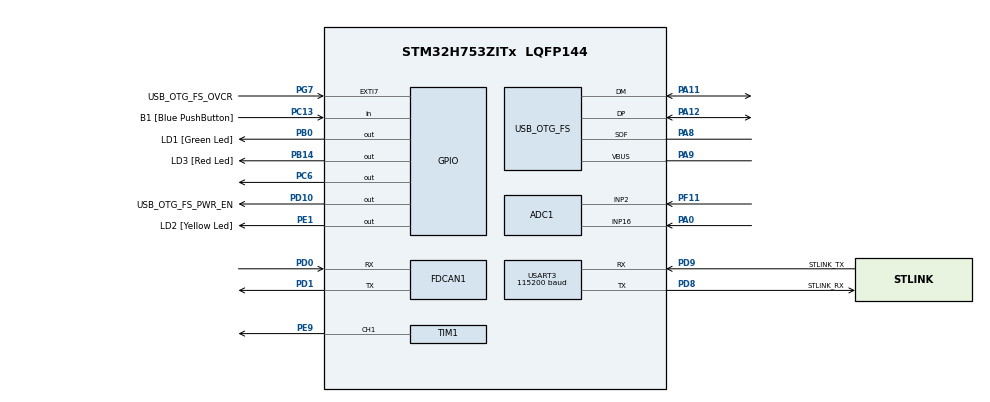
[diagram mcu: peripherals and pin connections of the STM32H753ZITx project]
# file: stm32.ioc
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ADC1.Channel-0\#ChannelRegularConversion=ADC_CHANNEL_16
ADC1.Channel-1\#ChannelRegularConversion=ADC_CHANNEL_2
ADC1.ConversionDataManagement=ADC_CONVERSIONDATA_DMA_CIRCULAR
ADC1.EOCSelection=ADC_EOC_SEQ_CONV
ADC1.NbrOfConversion=2
ADC1.NbrOfConversionFlag=1
ADC1.OffsetNumber-0\#ChannelRegularConversion=ADC_OFFSET_NONE
ADC1.OffsetNumber-1\#ChannelRegularConversion=ADC_OFFSET_NONE
ADC1.OffsetSignedSaturation-0\#ChannelRegularConversion=DISABLE
ADC1.OffsetSignedSaturation-1\#ChannelRegularConversion=DISABLE
ADC1.Overrun=ADC_OVR_DATA_OVERWRITTEN
ADC1.Rank-0\#ChannelRegularConversion=1
ADC1.Rank-1\#ChannelRegularConversion=2
ADC1.SamplingTime-0\#ChannelRegularConversion=ADC_SAMPLETIME_810CYCLES_5
ADC1.SamplingTime-1\#ChannelRegularConversion=ADC_SAMPLETIME_810CYCLES_5
ADC1.master=1
CORTEX_M7.AccessPermission-Cortex_Memory_Protection_Unit_Region0_Settings=MPU_REGION_FULL_ACCESS
CORTEX_M7.BaseAddress-Cortex_Memory_Protection_Unit_Region0_Settings=0x30000000
CORTEX_M7.CPU_DCache=Enabled
CORTEX_M7.CPU_ICache=Enabled
CORTEX_M7.DisableExec-Cortex_Memory_Protection_Unit_Region0_Settings=MPU_INSTRUCTION_ACCESS_DISABLE
CORTEX_M7.Enable-Cortex_Memory_Protection_Unit_Region0_Settings=MPU_REGION_ENABLE
CORTEX_M7.IsShareable-Cortex_Memory_Protection_Unit_Region0_Settings=MPU_ACCESS_SHAREABLE
CORTEX_M7.MPU_Control=MPU_PRIVILEGED_DEFAULT
CORTEX_M7.Size-Cortex_Memory_Protection_Unit_Region0_Settings=MPU_REGION_SIZE_256KB
Dma.ADC1.0.Direction=DMA_PERIPH_TO_MEMORY
Dma.ADC1.0.EventEnable=DISABLE
Dma.ADC1.0.FIFOMode=DMA_FIFOMODE_DISABLE
Dma.ADC1.0.Instance=DMA1_Stream0
Dma.ADC1.0.MemDataAlignment=DMA_MDATAALIGN_HALFWORD
Dma.ADC1.0.MemInc=DMA_MINC_ENABLE
Dma.ADC1.0.Mode=DMA_CIRCULAR
Dma.ADC1.0.PeriphDataAlignment=DMA_PDATAALIGN_HALFWORD
Dma.ADC1.0.PeriphInc=DMA_PINC_DISABLE
Dma.ADC1.0.Polarity=HAL_DMAMUX_REQ_GEN_RISING
Dma.ADC1.0.Priority=DMA_PRIORITY_LOW
Dma.ADC1.0.RequestNumber=1
Dma.ADC1.0.SignalID=NONE
Dma.ADC1.0.SyncEnable=DISABLE
Dma.ADC1.0.SyncPolarity=HAL_DMAMUX_SYNC_NO_EVENT
Dma.ADC1.0.SyncRequestNumber=1
Dma.ADC1.0.SyncSignalID=NONE
Dma.Request0=ADC1
FDCAN1.CalculateBaudRateNominal=500000
FDCAN1.CalculateTimeBitNominal=2000
FDCAN1.CalculateTimeQuantumNominal=250.0
FDCAN1.ClockCalibrationCCU=DISABLE
FDCAN1.Mode=FDCAN_MODE_INTERNAL_LOOPBACK
FDCAN1.NominalPrescaler=2
FDCAN1.NominalTimeSeg2=5
Mcu.Family=STM32H7
Mcu.Name=STM32H753ZITx
Mcu.Package=LQFP144
NVIC.ADC_IRQn=true\:0\:0\:true\:false\:true\:true\:true\:true
NVIC.DMA1_Stream0_IRQn=true\:0\:0\:true\:false\:true\:false\:true\:true
NVIC.PriorityGroup=NVIC_PRIORITYGROUP_4
PA0.Mode=IN16-Single-Ended
PA0.Signal=ADC1_INP16
PA1.Signal=ETH_REF_CLK
PA11.Mode=Device_Only
PA11.Signal=USB_OTG_FS_DM
PA12.Mode=Device_Only
PA12.Signal=USB_OTG_FS_DP
PA2.Signal=ETH_MDIO
PA7.Signal=ETH_CRS_DV
PA8.Mode=Activate_SOF_FS
PA8.Signal=USB_OTG_FS_SOF
PA9.Mode=Activate_VBUS
PA9.Signal=USB_OTG_FS_VBUS
PB0.GPIO_Label=LD1 [Green Led]
PB0.Signal=GPIO_Output
PB13.Signal=ETH_TXD1
PB14.GPIO_Label=LD3 [Red Led]
PB14.Signal=GPIO_Output
PC1.Signal=ETH_MDC
PC13.GPIO_Label=B1 [Blue PushButton]
PC13.Signal=GPIO_Input
PC14-OSC32_IN\ (OSC32_IN).Mode=LSE-External-Oscillator
PC14-OSC32_IN\ (OSC32_IN).Signal=RCC_OSC32_IN
PC15-OSC32_OUT\ (OSC32_OUT).Mode=LSE-External-Oscillator
PC15-OSC32_OUT\ (OSC32_OUT).Signal=RCC_OSC32_OUT
PC4.Signal=ETH_RXD0
PC5.Signal=ETH_RXD1
PC6.Signal=GPIO_Output
PD0.Mode=FDCAN_Activate
PD0.Signal=FDCAN1_RX
PD1.Mode=FDCAN_Activate
PD1.Signal=FDCAN1_TX
PD10.GPIO_Label=USB_OTG_FS_PWR_EN
PD10.Signal=GPIO_Output
PD8.GPIO_Label=STLINK_RX
PD8.Mode=Asynchronous
PD8.Signal=USART3_TX
PD9.GPIO_Label=STLINK_TX
PD9.Mode=Asynchronous
PD9.Signal=USART3_RX
PE1.GPIO_Label=LD2 [Yellow Led]
PE1.Signal=GPIO_Output
PE9.Signal=S_TIM1_CH1
PF11.Mode=IN2-Single-Ended
PF11.Signal=ADC1_INP2
PG11.Signal=ETH_TX_EN
PG13.Signal=ETH_TXD0
PG7.GPIO_Label=USB_OTG_FS_OVCR
PG7.Signal=GPXTI7
PH0-OSC_IN\ (PH0).Mode=HSE-External-Oscillator
PH0-OSC_IN\ (PH0).Signal=RCC_OSC_IN
PH1-OSC_OUT\ (PH1).Mode=HSE-External-Oscillator
PH1-OSC_OUT\ (PH1).Signal=RCC_OSC_OUT
ProjectManager.HeapSize=0x200
ProjectManager.StackSize=0x400
ProjectManager.TargetToolchain=Makefile
RCC.ADCFreq_Value=76000000
RCC.APB1Freq_Value=32000000
RCC.APB2Freq_Value=64000000
RCC.APB3Freq_Value=64000000
RCC.APB4Freq_Value=64000000
RCC.CortexFreq_Value=64000000
RCC.D2PPRE1=RCC_APB1_DIV2
RCC.DIVM1=1
RCC.DIVM2=1
RCC.DIVN1=19
RCC.DIVN2=19
RCC.DIVQ1=3
RCC.FDCANCLockSelection=RCC_FDCANCLKSOURCE_HSE
RCC.HCLKFreq_Value=64000000
RCC.HSE_VALUE=8000000
RCC.PLL2FRACN=0
RCC.PLL3FRACN=0
RCC.PLLFRACN=0
RCC.SYSCLKFreq_VALUE=64000000
RCC.USBFreq_Value=50666666.666666664
SH.S_TIM1_CH1.0=TIM1_CH1,PWM Generation1 CH1
TIM1.Channel-PWM\ Generation1\ CH1=TIM_CHANNEL_1
TIM1.Prescaler=0
USART3.AutoBaudRateEnableParam=UART_ADVFEATURE_AUTOBAUDRATE_DISABLE
USART3.BaudRate=115200
USART3.ClockPrescaler=PRESCALER_DIV1
USART3.DMADisableonRxErrorParam=ADVFEATURE_DMA_ENABLEONRXERROR
USART3.DataInvertParam=ADVFEATURE_DATAINV_DISABLE
USART3.FIFOMode=FIFOMODE_DISABLE
USART3.MSBFirstParam=ADVFEATURE_MSBFIRST_DISABLE
USART3.Mode=MODE_TX_RX
USART3.OneBitSampling=UART_ONE_BIT_SAMPLE_DISABLE
USART3.OverSampling=UART_OVERSAMPLING_16
USART3.OverrunDisableParam=ADVFEATURE_OVERRUN_ENABLE
USART3.Parity=PARITY_NONE
USART3.RXFIFOThreshold=RXFIFO_THRESHOLD_1EIGHTHFULL
USART3.RxPinLevelInvertParam=ADVFEATURE_RXINV_DISABLE
USART3.StopBits=STOPBITS_1
USART3.SwapParam=ADVFEATURE_SWAP_DISABLE
USART3.TXFIFOThreshold=TXFIFO_THRESHOLD_1EIGHTHFULL
USART3.TxPinLevelInvertParam=ADVFEATURE_TXINV_DISABLE
USART3.VirtualMode-Asynchronous=VM_ASYNC
USART3.WordLength=WORDLENGTH_8B
USB_OTG_FS.Sof_enable=ENABLE
USB_OTG_FS.VirtualMode=Device_Only
USB_OTG_FS.battery_charging_enable=ENABLE
USB_OTG_FS.low_power_enable=DISABLE
USB_OTG_FS.lpm_enable=DISABLE
USB_OTG_FS.use_dedicated_ep1=DISABLE
USB_OTG_FS.vbus_sensing_enable=ENABLE
VP_MEMORYMAP_VS_MEMORYMAP.Mode=CurAppReg
board=NUCLEO-H753ZI

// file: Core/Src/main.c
/* USER CODE BEGIN Header */
/**
  ******************************************************************************
  * @file           : main.c
  * @brief          : Main program body
  ******************************************************************************
  * @attention
  *
  * Copyright (c) 2025 STMicroelectronics.
  * All rights reserved.
  *
  * This software is licensed under terms that can be found in the LICENSE file
  * in the root directory of this software component.
  * If no LICENSE file comes with this software, it is provided AS-IS.
  *
  ******************************************************************************
  */
/* USER CODE END Header */
#include "main.h"

/* USER CODE BEGIN Includes */

#include <entry.h>

/* USER CODE END Includes */

ADC_HandleTypeDef hadc1;
DMA_HandleTypeDef hdma_adc1;

FDCAN_HandleTypeDef hfdcan1;

TIM_HandleTypeDef htim1;

UART_HandleTypeDef huart3;

PCD_HandleTypeDef hpcd_USB_OTG_FS;

void SystemClock_Config(void);
static void MPU_Config(void);
static void MX_GPIO_Init(void);
static void MX_DMA_Init(void);
static void MX_USART3_UART_Init(void);
static void MX_USB_OTG_FS_PCD_Init(void);
static void MX_ADC1_Init(void);
static void MX_TIM1_Init(void);
static void MX_FDCAN1_Init(void);

int main(void)
{

  /* MPU Configuration--------------------------------------------------------*/
  MPU_Config();

  /* Enable the CPU Cache */

  /* Enable I-Cache---------------------------------------------------------*/
  SCB_EnableICache();

  /* Enable D-Cache---------------------------------------------------------*/
  SCB_EnableDCache();

  /* MCU Configuration--------------------------------------------------------*/

  /* Reset of all peripherals, Initializes the Flash interface and the Systick. */
  HAL_Init();

  /* Configure the system clock */
  SystemClock_Config();

  /* Initialize all configured peripherals */
  MX_GPIO_Init();
  MX_DMA_Init();
  MX_USART3_UART_Init();
  MX_USB_OTG_FS_PCD_Init();
  MX_ADC1_Init();
  MX_TIM1_Init();
  MX_FDCAN1_Init();
  /* USER CODE BEGIN 2 */

  __initHandler();

  /* USER CODE END 2 */

  /* Infinite loop */
  while (1)
  {

  }
}

void SystemClock_Config(void)
{
  RCC_OscInitTypeDef RCC_OscInitStruct = {0};
  RCC_ClkInitTypeDef RCC_ClkInitStruct = {0};

  /** Supply configuration update enable
  */
  HAL_PWREx_ConfigSupply(PWR_LDO_SUPPLY);

  /** Configure the main internal regulator output voltage
  */
  __HAL_PWR_VOLTAGESCALING_CONFIG(PWR_REGULATOR_VOLTAGE_SCALE3);

  while(!__HAL_PWR_GET_FLAG(PWR_FLAG_VOSRDY)) {}

  /** Initializes the RCC Oscillators according to the specified parameters
  * in the RCC_OscInitTypeDef structure.
  */
  RCC_OscInitStruct.OscillatorType = RCC_OSCILLATORTYPE_HSI|RCC_OSCILLATORTYPE_HSE;
  RCC_OscInitStruct.HSEState = RCC_HSE_ON;
  RCC_OscInitStruct.HSIState = RCC_HSI_DIV1;
  RCC_OscInitStruct.HSICalibrationValue = RCC_HSICALIBRATION_DEFAULT;
  RCC_OscInitStruct.PLL.PLLState = RCC_PLL_ON;
  RCC_OscInitStruct.PLL.PLLSource = RCC_PLLSOURCE_HSE;
  RCC_OscInitStruct.PLL.PLLM = 1;
  RCC_OscInitStruct.PLL.PLLN = 19;
  RCC_OscInitStruct.PLL.PLLP = 2;
  RCC_OscInitStruct.PLL.PLLQ = 3;
  RCC_OscInitStruct.PLL.PLLR = 2;
  RCC_OscInitStruct.PLL.PLLRGE = RCC_PLL1VCIRANGE_3;
  RCC_OscInitStruct.PLL.PLLVCOSEL = RCC_PLL1VCOMEDIUM;
  RCC_OscInitStruct.PLL.PLLFRACN = 0;
  if (HAL_RCC_OscConfig(&RCC_OscInitStruct) != HAL_OK)
  {
    Error_Handler();
  }

  /** Initializes the CPU, AHB and APB buses clocks
  */
  RCC_ClkInitStruct.ClockType = RCC_CLOCKTYPE_HCLK|RCC_CLOCKTYPE_SYSCLK
                              |RCC_CLOCKTYPE_PCLK1|RCC_CLOCKTYPE_PCLK2
                              |RCC_CLOCKTYPE_D3PCLK1|RCC_CLOCKTYPE_D1PCLK1;
  RCC_ClkInitStruct.SYSCLKSource = RCC_SYSCLKSOURCE_HSI;
  RCC_ClkInitStruct.SYSCLKDivider = RCC_SYSCLK_DIV1;
  RCC_ClkInitStruct.AHBCLKDivider = RCC_HCLK_DIV1;
  RCC_ClkInitStruct.APB3CLKDivider = RCC_APB3_DIV1;
  RCC_ClkInitStruct.APB1CLKDivider = RCC_APB1_DIV2;
  RCC_ClkInitStruct.APB2CLKDivider = RCC_APB2_DIV1;
  RCC_ClkInitStruct.APB4CLKDivider = RCC_APB4_DIV1;

  if (HAL_RCC_ClockConfig(&RCC_ClkInitStruct, FLASH_LATENCY_1) != HAL_OK)
  {
    Error_Handler();
  }
}

static void MX_ADC1_Init(void)
{

  ADC_MultiModeTypeDef multimode = {0};
  ADC_ChannelConfTypeDef sConfig = {0};

  /** Common config
  */
  hadc1.Instance = ADC1;
  hadc1.Init.ScanConvMode = ADC_SCAN_ENABLE;
  hadc1.Init.EOCSelection = ADC_EOC_SEQ_CONV;
  hadc1.Init.LowPowerAutoWait = DISABLE;
  hadc1.Init.ContinuousConvMode = DISABLE;
  hadc1.Init.NbrOfConversion = 2;
  hadc1.Init.DiscontinuousConvMode = DISABLE;
  hadc1.Init.ExternalTrigConv = ADC_SOFTWARE_START;
  hadc1.Init.ExternalTrigConvEdge = ADC_EXTERNALTRIGCONVEDGE_NONE;
  hadc1.Init.ConversionDataManagement = ADC_CONVERSIONDATA_DMA_CIRCULAR;
  hadc1.Init.Overrun = ADC_OVR_DATA_OVERWRITTEN;
  hadc1.Init.LeftBitShift = ADC_LEFTBITSHIFT_NONE;
  hadc1.Init.OversamplingMode = DISABLE;
  hadc1.Init.Oversampling.Ratio = 1;
  if (HAL_ADC_Init(&hadc1) != HAL_OK)
  {
    Error_Handler();
  }
  hadc1.Init.ClockPrescaler = ADC_CLOCK_ASYNC_DIV2;
  hadc1.Init.Resolution = ADC_RESOLUTION_16B;
  if (HAL_ADC_Init(&hadc1) != HAL_OK)
  {
    Error_Handler();
  }

  /** Configure the ADC multi-mode
  */
  multimode.Mode = ADC_MODE_INDEPENDENT;
  if (HAL_ADCEx_MultiModeConfigChannel(&hadc1, &multimode) != HAL_OK)
  {
    Error_Handler();
  }

  /** Configure Regular Channel
  */
  sConfig.Channel = ADC_CHANNEL_16;
  sConfig.Rank = ADC_REGULAR_RANK_1;
  sConfig.SamplingTime = ADC_SAMPLETIME_810CYCLES_5;
  sConfig.SingleDiff = ADC_SINGLE_ENDED;
  sConfig.OffsetNumber = ADC_OFFSET_NONE;
  sConfig.Offset = 0;
  sConfig.OffsetSignedSaturation = DISABLE;
  if (HAL_ADC_ConfigChannel(&hadc1, &sConfig) != HAL_OK)
  {
    Error_Handler();
  }

  /** Configure Regular Channel
  */
  sConfig.Channel = ADC_CHANNEL_2;
  sConfig.Rank = ADC_REGULAR_RANK_2;
  if (HAL_ADC_ConfigChannel(&hadc1, &sConfig) != HAL_OK)
  {
    Error_Handler();
  }

}

static void MX_FDCAN1_Init(void)
{

  hfdcan1.Instance = FDCAN1;
  hfdcan1.Init.FrameFormat = FDCAN_FRAME_CLASSIC;
  hfdcan1.Init.Mode = FDCAN_MODE_INTERNAL_LOOPBACK;
  hfdcan1.Init.AutoRetransmission = DISABLE;
  hfdcan1.Init.TransmitPause = DISABLE;
  hfdcan1.Init.ProtocolException = DISABLE;
  hfdcan1.Init.NominalPrescaler = 2;
  hfdcan1.Init.NominalSyncJumpWidth = 1;
  hfdcan1.Init.NominalTimeSeg1 = 2;
  hfdcan1.Init.NominalTimeSeg2 = 5;
  hfdcan1.Init.DataPrescaler = 1;
  hfdcan1.Init.DataSyncJumpWidth = 1;
  hfdcan1.Init.DataTimeSeg1 = 1;
  hfdcan1.Init.DataTimeSeg2 = 1;
  hfdcan1.Init.MessageRAMOffset = 0;
  hfdcan1.Init.StdFiltersNbr = 0;
  hfdcan1.Init.ExtFiltersNbr = 0;
  hfdcan1.Init.RxFifo0ElmtsNbr = 0;
  hfdcan1.Init.RxFifo0ElmtSize = FDCAN_DATA_BYTES_8;
  hfdcan1.Init.RxFifo1ElmtsNbr = 0;
  hfdcan1.Init.RxFifo1ElmtSize = FDCAN_DATA_BYTES_8;
  hfdcan1.Init.RxBuffersNbr = 0;
  hfdcan1.Init.RxBufferSize = FDCAN_DATA_BYTES_8;
  hfdcan1.Init.TxEventsNbr = 0;
  hfdcan1.Init.TxBuffersNbr = 0;
  hfdcan1.Init.TxFifoQueueElmtsNbr = 0;
  hfdcan1.Init.TxFifoQueueMode = FDCAN_TX_FIFO_OPERATION;
  hfdcan1.Init.TxElmtSize = FDCAN_DATA_BYTES_8;
  if (HAL_FDCAN_Init(&hfdcan1) != HAL_OK)
  {
    Error_Handler();
  }

}

static void MX_TIM1_Init(void)
{

  TIM_MasterConfigTypeDef sMasterConfig = {0};
  TIM_OC_InitTypeDef sConfigOC = {0};
  TIM_BreakDeadTimeConfigTypeDef sBreakDeadTimeConfig = {0};

  htim1.Instance = TIM1;
  htim1.Init.Prescaler = 0;
  htim1.Init.CounterMode = TIM_COUNTERMODE_UP;
  htim1.Init.Period = 65535;
  htim1.Init.ClockDivision = TIM_CLOCKDIVISION_DIV1;
  htim1.Init.RepetitionCounter = 0;
  htim1.Init.AutoReloadPreload = TIM_AUTORELOAD_PRELOAD_DISABLE;
  if (HAL_TIM_PWM_Init(&htim1) != HAL_OK)
  {
    Error_Handler();
  }
  sMasterConfig.MasterOutputTrigger = TIM_TRGO_RESET;
  sMasterConfig.MasterOutputTrigger2 = TIM_TRGO2_RESET;
  sMasterConfig.MasterSlaveMode = TIM_MASTERSLAVEMODE_DISABLE;
  if (HAL_TIMEx_MasterConfigSynchronization(&htim1, &sMasterConfig) != HAL_OK)
  {
    Error_Handler();
  }
  sConfigOC.OCMode = TIM_OCMODE_PWM1;
  sConfigOC.Pulse = 0;
  sConfigOC.OCPolarity = TIM_OCPOLARITY_HIGH;
  sConfigOC.OCNPolarity = TIM_OCNPOLARITY_HIGH;
  sConfigOC.OCFastMode = TIM_OCFAST_DISABLE;
  sConfigOC.OCIdleState = TIM_OCIDLESTATE_RESET;
  sConfigOC.OCNIdleState = TIM_OCNIDLESTATE_RESET;
  if (HAL_TIM_PWM_ConfigChannel(&htim1, &sConfigOC, TIM_CHANNEL_1) != HAL_OK)
  {
    Error_Handler();
  }
  sBreakDeadTimeConfig.OffStateRunMode = TIM_OSSR_DISABLE;
  sBreakDeadTimeConfig.OffStateIDLEMode = TIM_OSSI_DISABLE;
  sBreakDeadTimeConfig.LockLevel = TIM_LOCKLEVEL_OFF;
  sBreakDeadTimeConfig.DeadTime = 0;
  sBreakDeadTimeConfig.BreakState = TIM_BREAK_DISABLE;
  sBreakDeadTimeConfig.BreakPolarity = TIM_BREAKPOLARITY_HIGH;
  sBreakDeadTimeConfig.BreakFilter = 0;
  sBreakDeadTimeConfig.Break2State = TIM_BREAK2_DISABLE;
  sBreakDeadTimeConfig.Break2Polarity = TIM_BREAK2POLARITY_HIGH;
  sBreakDeadTimeConfig.Break2Filter = 0;
  sBreakDeadTimeConfig.AutomaticOutput = TIM_AUTOMATICOUTPUT_DISABLE;
  if (HAL_TIMEx_ConfigBreakDeadTime(&htim1, &sBreakDeadTimeConfig) != HAL_OK)
  {
    Error_Handler();
  }
  HAL_TIM_MspPostInit(&htim1);

}

static void MX_USART3_UART_Init(void)
{

  huart3.Instance = USART3;
  huart3.Init.BaudRate = 115200;
  huart3.Init.WordLength = UART_WORDLENGTH_8B;
  huart3.Init.StopBits = UART_STOPBITS_1;
  huart3.Init.Parity = UART_PARITY_NONE;
  huart3.Init.Mode = UART_MODE_TX_RX;
  huart3.Init.HwFlowCtl = UART_HWCONTROL_NONE;
  huart3.Init.OverSampling = UART_OVERSAMPLING_16;
  huart3.Init.OneBitSampling = UART_ONE_BIT_SAMPLE_DISABLE;
  huart3.Init.ClockPrescaler = UART_PRESCALER_DIV1;
  huart3.AdvancedInit.AdvFeatureInit = UART_ADVFEATURE_NO_INIT;
  if (HAL_UART_Init(&huart3) != HAL_OK)
  {
    Error_Handler();
  }
  if (HAL_UARTEx_SetTxFifoThreshold(&huart3, UART_TXFIFO_THRESHOLD_1_8) != HAL_OK)
  {
    Error_Handler();
  }
  if (HAL_UARTEx_SetRxFifoThreshold(&huart3, UART_RXFIFO_THRESHOLD_1_8) != HAL_OK)
  {
    Error_Handler();
  }
  if (HAL_UARTEx_DisableFifoMode(&huart3) != HAL_OK)
  {
    Error_Handler();
  }

}

static void MX_USB_OTG_FS_PCD_Init(void)
{

  hpcd_USB_OTG_FS.Instance = USB_OTG_FS;
  hpcd_USB_OTG_FS.Init.dev_endpoints = 9;
  hpcd_USB_OTG_FS.Init.speed = PCD_SPEED_FULL;
  hpcd_USB_OTG_FS.Init.dma_enable = DISABLE;
  hpcd_USB_OTG_FS.Init.phy_itface = PCD_PHY_EMBEDDED;
  hpcd_USB_OTG_FS.Init.Sof_enable = ENABLE;
  hpcd_USB_OTG_FS.Init.low_power_enable = DISABLE;
  hpcd_USB_OTG_FS.Init.lpm_enable = DISABLE;
  hpcd_USB_OTG_FS.Init.battery_charging_enable = ENABLE;
  hpcd_USB_OTG_FS.Init.vbus_sensing_enable = ENABLE;
  hpcd_USB_OTG_FS.Init.use_dedicated_ep1 = DISABLE;
  if (HAL_PCD_Init(&hpcd_USB_OTG_FS) != HAL_OK)
  {
    Error_Handler();
  }

}

static void MX_DMA_Init(void)
{

  /* DMA controller clock enable */
  __HAL_RCC_DMA1_CLK_ENABLE();

  /* DMA interrupt init */
  /* DMA1_Stream0_IRQn interrupt configuration */
  HAL_NVIC_SetPriority(DMA1_Stream0_IRQn, 0, 0);
  HAL_NVIC_EnableIRQ(DMA1_Stream0_IRQn);

}

static void MX_GPIO_Init(void)
{
  GPIO_InitTypeDef GPIO_InitStruct = {0};

  /* GPIO Ports Clock Enable */
  __HAL_RCC_GPIOC_CLK_ENABLE();
  __HAL_RCC_GPIOH_CLK_ENABLE();
  __HAL_RCC_GPIOA_CLK_ENABLE();
  __HAL_RCC_GPIOB_CLK_ENABLE();
  __HAL_RCC_GPIOF_CLK_ENABLE();
  __HAL_RCC_GPIOE_CLK_ENABLE();
  __HAL_RCC_GPIOD_CLK_ENABLE();
  __HAL_RCC_GPIOG_CLK_ENABLE();

  /*Configure GPIO pin Output Level */
  HAL_GPIO_WritePin(GPIOB, LD1_Pin|LD3_Pin, GPIO_PIN_RESET);

  /*Configure GPIO pin Output Level */
  HAL_GPIO_WritePin(USB_OTG_FS_PWR_EN_GPIO_Port, USB_OTG_FS_PWR_EN_Pin, GPIO_PIN_RESET);

  /*Configure GPIO pin Output Level */
  HAL_GPIO_WritePin(GPIOC, GPIO_PIN_6, GPIO_PIN_RESET);

  /*Configure GPIO pin Output Level */
  HAL_GPIO_WritePin(LD2_GPIO_Port, LD2_Pin, GPIO_PIN_RESET);

  /*Configure GPIO pin : B1_Pin */
  GPIO_InitStruct.Pin = B1_Pin;
  GPIO_InitStruct.Mode = GPIO_MODE_INPUT;
  GPIO_InitStruct.Pull = GPIO_NOPULL;
  HAL_GPIO_Init(B1_GPIO_Port, &GPIO_InitStruct);

  /*Configure GPIO pins : PC1 PC4 PC5 */
  GPIO_InitStruct.Pin = GPIO_PIN_1|GPIO_PIN_4|GPIO_PIN_5;
  GPIO_InitStruct.Mode = GPIO_MODE_AF_PP;
  GPIO_InitStruct.Pull = GPIO_NOPULL;
  GPIO_InitStruct.Speed = GPIO_SPEED_FREQ_LOW;
  GPIO_InitStruct.Alternate = GPIO_AF11_ETH;
  HAL_GPIO_Init(GPIOC, &GPIO_InitStruct);

  /*Configure GPIO pins : PA1 PA2 PA7 */
  GPIO_InitStruct.Pin = GPIO_PIN_1|GPIO_PIN_2|GPIO_PIN_7;
  GPIO_InitStruct.Mode = GPIO_MODE_AF_PP;
  GPIO_InitStruct.Pull = GPIO_NOPULL;
  GPIO_InitStruct.Speed = GPIO_SPEED_FREQ_LOW;
  GPIO_InitStruct.Alternate = GPIO_AF11_ETH;
  HAL_GPIO_Init(GPIOA, &GPIO_InitStruct);

  /*Configure GPIO pins : LD1_Pin LD3_Pin */
  GPIO_InitStruct.Pin = LD1_Pin|LD3_Pin;
  GPIO_InitStruct.Mode = GPIO_MODE_OUTPUT_PP;
  GPIO_InitStruct.Pull = GPIO_NOPULL;
  GPIO_InitStruct.Speed = GPIO_SPEED_FREQ_LOW;
  HAL_GPIO_Init(GPIOB, &GPIO_InitStruct);

  /*Configure GPIO pin : PB13 */
  GPIO_InitStruct.Pin = GPIO_PIN_13;
  GPIO_InitStruct.Mode = GPIO_MODE_AF_PP;
  GPIO_InitStruct.Pull = GPIO_NOPULL;
  GPIO_InitStruct.Speed = GPIO_SPEED_FREQ_LOW;
  GPIO_InitStruct.Alternate = GPIO_AF11_ETH;
  HAL_GPIO_Init(GPIOB, &GPIO_InitStruct);

  /*Configure GPIO pin : USB_OTG_FS_PWR_EN_Pin */
  GPIO_InitStruct.Pin = USB_OTG_FS_PWR_EN_Pin;
  GPIO_InitStruct.Mode = GPIO_MODE_OUTPUT_PP;
  GPIO_InitStruct.Pull = GPIO_NOPULL;
  GPIO_InitStruct.Speed = GPIO_SPEED_FREQ_LOW;
  HAL_GPIO_Init(USB_OTG_FS_PWR_EN_GPIO_Port, &GPIO_InitStruct);

  /*Configure GPIO pin : USB_OTG_FS_OVCR_Pin */
  GPIO_InitStruct.Pin = USB_OTG_FS_OVCR_Pin;
  GPIO_InitStruct.Mode = GPIO_MODE_IT_RISING;
  GPIO_InitStruct.Pull = GPIO_NOPULL;
  HAL_GPIO_Init(USB_OTG_FS_OVCR_GPIO_Port, &GPIO_InitStruct);

  /*Configure GPIO pin : PC6 */
  GPIO_InitStruct.Pin = GPIO_PIN_6;
  GPIO_InitStruct.Mode = GPIO_MODE_OUTPUT_PP;
  GPIO_InitStruct.Pull = GPIO_NOPULL;
  GPIO_InitStruct.Speed = GPIO_SPEED_FREQ_LOW;
  HAL_GPIO_Init(GPIOC, &GPIO_InitStruct);

  /*Configure GPIO pins : PG11 PG13 */
  GPIO_InitStruct.Pin = GPIO_PIN_11|GPIO_PIN_13;
  GPIO_InitStruct.Mode = GPIO_MODE_AF_PP;
  GPIO_InitStruct.Pull = GPIO_NOPULL;
  GPIO_InitStruct.Speed = GPIO_SPEED_FREQ_LOW;
  GPIO_InitStruct.Alternate = GPIO_AF11_ETH;
  HAL_GPIO_Init(GPIOG, &GPIO_InitStruct);

  /*Configure GPIO pin : LD2_Pin */
  GPIO_InitStruct.Pin = LD2_Pin;
  GPIO_InitStruct.Mode = GPIO_MODE_OUTPUT_PP;
  GPIO_InitStruct.Pull = GPIO_NOPULL;
  GPIO_InitStruct.Speed = GPIO_SPEED_FREQ_LOW;
  HAL_GPIO_Init(LD2_GPIO_Port, &GPIO_InitStruct);

}

 /* MPU Configuration */

void MPU_Config(void)
{
  MPU_Region_InitTypeDef MPU_InitStruct = {0};

  /* Disables the MPU */
  HAL_MPU_Disable();

  /** Initializes and configures the Region and the memory to be protected
  */
  MPU_InitStruct.Enable = MPU_REGION_ENABLE;
  MPU_InitStruct.Number = MPU_REGION_NUMBER0;
  MPU_InitStruct.BaseAddress = 0x30000000;
  MPU_InitStruct.Size = MPU_REGION_SIZE_256KB;
  MPU_InitStruct.SubRegionDisable = 0x0;
  MPU_InitStruct.TypeExtField = MPU_TEX_LEVEL0;
  MPU_InitStruct.AccessPermission = MPU_REGION_FULL_ACCESS;
  MPU_InitStruct.DisableExec = MPU_INSTRUCTION_ACCESS_DISABLE;
  MPU_InitStruct.IsShareable = MPU_ACCESS_SHAREABLE;
  MPU_InitStruct.IsCacheable = MPU_ACCESS_NOT_CACHEABLE;
  MPU_InitStruct.IsBufferable = MPU_ACCESS_NOT_BUFFERABLE;

  HAL_MPU_ConfigRegion(&MPU_InitStruct);
  /* Enables the MPU */
  HAL_MPU_Enable(MPU_PRIVILEGED_DEFAULT);

}

void Error_Handler(void)
{
  __disable_irq();
  while (1)
  {
  }
}
